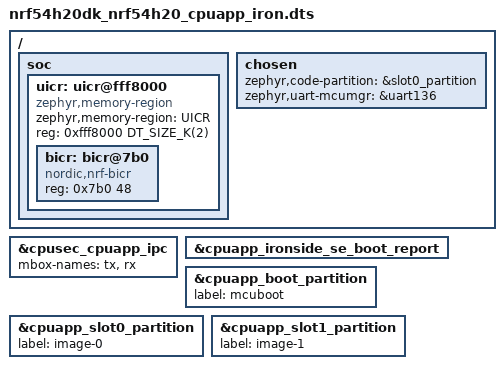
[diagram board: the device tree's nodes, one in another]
/*
 * Copyright (c) 2025 Nordic Semiconductor ASA
 *
 * SPDX-License-Identifier: Apache-2.0
 */

#include "nrf54h20dk_nrf54h20_cpuapp.dts"
#include "nrf54h20dk_nrf54h20-ipc_conf_iron.dtsi"
#include "nrf54h20dk_nrf54h20-memory_map_iron.dtsi"

/delete-node/ &cpusec_cpurad_ipc;
/delete-node/ &cpuapp_uicr;

/ {
	soc {
		uicr: uicr@fff8000 {
			compatible = "zephyr,memory-region", "nordic,nrf-uicr";
			zephyr,memory-region = "UICR";
			reg = <0xfff8000 DT_SIZE_K(2)>;
			#address-cells = <1>;
			#size-cells = <1>;
			ranges = <0x0 0xfff8000 DT_SIZE_K(2)>;

			bicr: bicr@7b0 {
				compatible = "nordic,nrf-bicr";
				reg = <0x7b0 48>;
			};
		};
	};
};

/ {
	chosen {
		zephyr,code-partition = &slot0_partition;
		zephyr,uart-mcumgr = &uart136;
	};
};

&cpusec_cpuapp_ipc {
	mbox-names = "tx", "rx";
	status = "okay";
};

ironside_se_boot_report: &cpuapp_ironside_se_boot_report {};

boot_partition: &cpuapp_boot_partition {
	label = "mcuboot";
};

slot0_partition: &cpuapp_slot0_partition {
	label = "image-0";
};

slot1_partition: &cpuapp_slot1_partition {
	label = "image-1";
};
